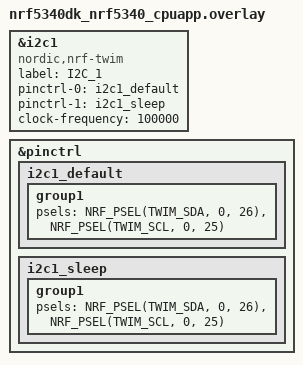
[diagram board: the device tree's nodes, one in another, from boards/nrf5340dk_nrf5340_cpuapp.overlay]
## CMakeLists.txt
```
# SPDX-License-Identifier: Apache-2.0

cmake_minimum_required(VERSION 3.20.0)
find_package(Zephyr REQUIRED HINTS $ENV{ZEPHYR_BASE})
project(max30100)

FILE(GLOB app_sources src/*.c)
target_sources(app PRIVATE ${app_sources})
```

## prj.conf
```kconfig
CONFIG_STDOUT_CONSOLE=y
CONFIG_LOG=y
CONFIG_I2C=y
CONFIG_SENSOR=y
CONFIG_SENSOR_LOG_LEVEL_DBG=y

CONFIG_ASSERT=y

# Logging
CONFIG_UART_CONSOLE=y
CONFIG_SERIAL=y


# Stacks and heaps
CONFIG_MAIN_STACK_SIZE=16384
CONFIG_HEAP_MEM_POOL_SIZE=16384

# I2C
CONFIG_NRFX_TWIM1=y


# Rebooot
CONFIG_REBOOT=n
CONFIG_RESET_ON_FATAL_ERROR=n
```

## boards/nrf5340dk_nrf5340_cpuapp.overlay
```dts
&i2c1 {
	status = "okay";
	compatible = "nordic,nrf-twim";
	label = "I2C_1";
	pinctrl-0 = <&i2c1_default>;
	pinctrl-1 = <&i2c1_sleep>;
	pinctrl-names = "default", "sleep";
	clock-frequency = <100000>; 
};

&pinctrl {
	i2c1_default: i2c1_default{
		group1 {
			psels = <NRF_PSEL(TWIM_SDA, 0, 26)>,
				<NRF_PSEL(TWIM_SCL, 0, 25)>;
		};
	};

	i2c1_sleep: i2c1_sleep{
		group1 {
			psels = <NRF_PSEL(TWIM_SDA, 0, 26)>,
				<NRF_PSEL(TWIM_SCL, 0, 25)>;
		};
	};
};
```

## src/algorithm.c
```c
#include "algorithm.h"

void maxim_heart_rate_and_oxygen_saturation(uint32_t *pun_ir_buffer, int32_t n_ir_buffer_length, uint32_t *pun_red_buffer, int32_t *pn_spo2, int8_t *pch_spo2_valid, int32_t *pn_heart_rate, int8_t *pch_hr_valid)
/**
* \brief        Calculate the heart rate and SpO2 level
* \par          Details
*               By detecting  peaks of PPG cycle and corresponding AC/DC of red/infra-red signal, the an_ratio for the SPO2 is computed.
*               Since this algorithm is aiming for Arm M0/M3. formaula for SPO2 did not achieve the accuracy due to register overflow.
*               Thus, accurate SPO2 is precalculated and save longo uch_spo2_table[] per each an_ratio.
*
* \param[in]    *pun_ir_buffer           - IR sensor data buffer
* \param[in]    n_ir_buffer_length      - IR sensor data buffer length
* \param[in]    *pun_red_buffer          - Red sensor data buffer
* \param[out]    *pn_spo2                - Calculated SpO2 value
* \param[out]    *pch_spo2_valid         - 1 if the calculated SpO2 value is valid
* \param[out]    *pn_heart_rate          - Calculated heart rate value
* \param[out]    *pch_hr_valid           - 1 if the calculated heart rate value is valid
*
* \retval       None
*/
{
    
  uint32_t un_ir_mean;
  int32_t k, n_i_ratio_count;
  int32_t i, n_exact_ir_valley_locs_count, n_middle_idx;
  int32_t n_th1, n_npks;   
  int32_t an_ir_valley_locs[15] ;
  int32_t n_peak_interval_sum;
  
  int32_t n_y_ac, n_x_ac;
  int32_t n_spo2_calc; 
  int32_t n_y_dc_max, n_x_dc_max; 
  int32_t n_y_dc_max_idx = 0;
  int32_t n_x_dc_max_idx = 0; 
  int32_t an_ratio[5], n_ratio_average; 
  int32_t n_nume, n_denom ;

  // calculates DC mean and subtract DC from ir
  un_ir_mean =0; 
  for (k=0 ; k<n_ir_buffer_length ; k++ ) un_ir_mean += pun_ir_buffer[k] ;
  un_ir_mean =un_ir_mean/n_ir_buffer_length ;
    
  // remove DC and invert signal so that we can use peak detector as valley detector
  for (k=0 ; k<n_ir_buffer_length ; k++ )  
    an_x[k] = -1*(pun_ir_buffer[k] - un_ir_mean) ; 
    
  // 4 pt Moving Average
  for(k=0; k< BUFFER_SIZE-MA4_SIZE; k++){
    an_x[k]=( an_x[k]+an_x[k+1]+ an_x[k+2]+ an_x[k+3])/(int32_t)4;        
  }
  // calculate threshold  
  n_th1=0; 
  for ( k=0 ; k<BUFFER_SIZE ;k++){
    n_th1 +=  an_x[k];
  }
  n_th1=  n_th1/ ( BUFFER_SIZE);
  if( n_th1<30) n_th1=30; // min allowed
  if( n_th1>60) n_th1=60; // max allowed

  for ( k=0 ; k<15;k++) an_ir_valley_locs[k]=0;
  // since we flipped signal, we use peak detector as valley detector
  maxim_find_peaks( an_ir_valley_locs, &n_npks, an_x, BUFFER_SIZE, n_th1, 4, 15 );//peak_height, peak_distance, max_num_peaks 
  n_peak_interval_sum =0;
  if (n_npks>=2){
    for (k=1; k<n_npks; k++) n_peak_interval_sum += (an_ir_valley_locs[k] -an_ir_valley_locs[k -1] ) ;
    n_peak_interval_sum =n_peak_interval_sum/(n_npks-1);
    *pn_heart_rate =(int32_t)( (FreqS*60)/ n_peak_interval_sum );
    *pch_hr_valid  = 1;
  }
  else  { 
    *pn_heart_rate = -999; // unable to calculate because # of peaks are too small
    *pch_hr_valid  = 0;
  }

  //  load raw value again for SPO2 calculation : RED(=y) and IR(=X)
  for (k=0 ; k<n_ir_buffer_length ; k++ )  {
      an_x[k] =  pun_ir_buffer[k] ; 
      an_y[k] =  pun_red_buffer[k] ; 
  }

  // find precise min near an_ir_valley_locs
  n_exact_ir_valley_locs_count =n_npks; 
  
  //using exact_ir_valley_locs , find ir-red DC andir-red AC for SPO2 calibration an_ratio
  //finding AC/DC maximum of raw

  n_ratio_average =0; 
  n_i_ratio_count = 0; 
  for(k=0; k< 5; k++) an_ratio[k]=0;
  for (k=0; k< n_exact_ir_valley_locs_count; k++){
    if (an_ir_valley_locs[k] > BUFFER_SIZE ){
      *pn_spo2 =  -999 ; // do not use SPO2 since valley loc is out of range
      *pch_spo2_valid  = 0; 
      return;
    }
  }
  // find max between two valley locations 
  // and use an_ratio betwen AC compoent of Ir & Red and DC compoent of Ir & Red for SPO2 
  for (k=0; k< n_exact_ir_valley_locs_count-1; k++){
    n_y_dc_max= -16777216 ; 
    n_x_dc_max= -16777216; 
    if (an_ir_valley_locs[k+1]-an_ir_valley_locs[k] >3){
        for (i=an_ir_valley_locs[k]; i< an_ir_valley_locs[k+1]; i++){
          if (an_x[i]> n_x_dc_max) {n_x_dc_max =an_x[i]; n_x_dc_max_idx=i;}
          if (an_y[i]> n_y_dc_max) {n_y_dc_max =an_y[i]; n_y_dc_max_idx=i;}
      }
      n_y_ac= (an_y[an_ir_valley_locs[k+1]] - an_y[an_ir_valley_locs[k] ] )*(n_y_dc_max_idx -an_ir_valley_locs[k]); //red
      n_y_ac=  an_y[an_ir_valley_locs[k]] + n_y_ac/ (an_ir_valley_locs[k+1] - an_ir_valley_locs[k])  ; 
      n_y_ac=  an_y[n_y_dc_max_idx] - n_y_ac;    // subracting linear DC compoenents from raw 
      n_x_ac= (an_x[an_ir_valley_locs[k+1]] - an_x[an_ir_valley_locs[k] ] )*(n_x_dc_max_idx -an_ir_valley_locs[k]); // ir
      n_x_ac=  an_x[an_ir_valley_locs[k]] + n_x_ac/ (an_ir_valley_locs[k+1] - an_ir_valley_locs[k]); 
      n_x_ac=  an_x[n_y_dc_max_idx] - n_x_ac;      // subracting linear DC compoenents from raw 
      n_nume=( n_y_ac *n_x_dc_max)>>7 ; //prepare X100 to preserve floating value
      n_denom= ( n_x_ac *n_y_dc_max)>>7;
      if (n_denom>0  && n_i_ratio_count <5 &&  n_nume != 0)
      {   
        an_ratio[n_i_ratio_count]= (n_nume*100)/n_denom ; //formular is ( n_y_ac *n_x_dc_max) / ( n_x_ac *n_y_dc_max) ;
        n_i_ratio_count++;
      }
    }
  }
  // choose median value since PPG signal may varies from beat to beat
  maxim_sort_ascend(an_ratio, n_i_ratio_count);
  n_middle_idx= n_i_ratio_count/2;

  if (n_middle_idx >1)
    n_ratio_average =( an_ratio[n_middle_idx-1] +an_ratio[n_middle_idx])/2; // use median
  else
    n_ratio_average = an_ratio[n_middle_idx ];

  if( n_ratio_average>2 && n_ratio_average <184){
    n_spo2_calc= uch_spo2_table[n_ratio_average] ;
    *pn_spo2 = n_spo2_calc ;
    *pch_spo2_valid  = 1;//  float_SPO2 =  -45.060*n_ratio_average* n_ratio_average/10000 + 30.354 *n_ratio_average/100 + 94.845 ;  // for comparison with table
  }
  else{
    *pn_spo2 =  -999 ; // do not use SPO2 since signal an_ratio is out of range
    *pch_spo2_valid  = 0; 
  }
}


void maxim_find_peaks( int32_t *pn_locs, int32_t *n_npks,  int32_t  *pn_x, int32_t n_size, int32_t n_min_height, int32_t n_min_distance, int32_t n_max_num )
/**
* \brief        Find peaks
* \par          Details
*               Find at most MAX_NUM peaks above MIN_HEIGHT separated by at least MIN_DISTANCE
*
* \retval       None
*/
{
  maxim_peaks_above_min_height( pn_locs, n_npks, pn_x, n_size, n_min_height );
  maxim_remove_close_peaks( pn_locs, n_npks, pn_x, n_min_distance );
  *n_npks = min( *n_npks, n_max_num );
}

void maxim_peaks_above_min_height( int32_t *pn_locs, int32_t *n_npks,  int32_t  *pn_x, int32_t n_size, int32_t n_min_height )
/**
* \brief        Find peaks above n_min_height
* \par          Details
*               Find all peaks above MIN_HEIGHT
*
* \retval       None
*/
{
  int32_t i = 1, n_width;
  *n_npks = 0;
  
  while (i < n_size-1){
    if (pn_x[i] > n_min_height && pn_x[i] > pn_x[i-1]){      // find left edge of potential peaks
      n_width = 1;
      while (i+n_width < n_size && pn_x[i] == pn_x[i+n_width])  // find flat peaks
        n_width++;
      if (pn_x[i] > pn_x[i+n_width] && (*n_npks) < 15 ){      // find right edge of peaks
        pn_locs[(*n_npks)++] = i;    
        // for flat peaks, peak location is left edge
        i += n_width+1;
      }
      else
        i += n_width;
    }
    else
      i++;
  }
}

void maxim_remove_close_peaks(int32_t *pn_locs, int32_t *pn_npks, int32_t *pn_x, int32_t n_min_distance)
/**
* \brief        Remove peaks
* \par          Details
*               Remove peaks separated by less than MIN_DISTANCE
*
* \retval       None
*/
{
    
  int32_t i, j, n_old_npks, n_dist;
    
  /* Order peaks from large to small */
  maxim_sort_indices_descend( pn_x, pn_locs, *pn_npks );

  for ( i = -1; i < *pn_npks; i++ ){
    n_old_npks = *pn_npks;
    *pn_npks = i+1;
    for ( j = i+1; j < n_old_npks; j++ ){
      n_dist =  pn_locs[j] - ( i == -1 ? -1 : pn_locs[i] ); // lag-zero peak of autocorr is at index -1
      if ( n_dist > n_min_distance || n_dist < -n_min_distance )
        pn_locs[(*pn_npks)++] = pn_locs[j];
    }
  }

  // Resort indices int32_to ascending order
  maxim_sort_ascend( pn_locs, *pn_npks );
}

void maxim_sort_ascend(int32_t  *pn_x, int32_t n_size) 
/**
* \brief        Sort array
* \par          Details
*               Sort array in ascending order (insertion sort algorithm)
*
* \retval       None
*/
{
  int32_t i, j, n_temp;
  for (i = 1; i < n_size; i++) {
    n_temp = pn_x[i];
    for (j = i; j > 0 && n_temp < pn_x[j-1]; j--)
        pn_x[j] = pn_x[j-1];
    pn_x[j] = n_temp;
  }
}

void maxim_sort_indices_descend(  int32_t  *pn_x, int32_t *pn_indx, int32_t n_size)
/**
* \brief        Sort indices
* \par          Details
*               Sort indices according to descending order (insertion sort algorithm)
*
* \retval       None
*/ 
{
  int32_t i, j, n_temp;
  for (i = 1; i < n_size; i++) {
    n_temp = pn_indx[i];
    for (j = i; j > 0 && pn_x[n_temp] > pn_x[pn_indx[j-1]]; j--)
      pn_indx[j] = pn_indx[j-1];
    pn_indx[j] = n_temp;
  }
}
```

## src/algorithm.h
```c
#include <stdbool.h>
#include <stdint.h>


#define FreqS 25    //sampling frequency
#define BUFFER_SIZE (FreqS * 4) 
#define MA4_SIZE 4 // DONOT CHANGE
#define min(x,y) ((x) < (y) ? (x) : (y)) //Defined in Arduino.h

//uch_spo2_table is approximated as  -45.060*ratioAverage* ratioAverage + 30.354 *ratioAverage + 94.845 ;
const uint8_t uch_spo2_table[184]={ 95, 95, 95, 96, 96, 96, 97, 97, 97, 97, 97, 98, 98, 98, 98, 98, 99, 99, 99, 99, 
              99, 99, 99, 99, 100, 100, 100, 100, 100, 100, 100, 100, 100, 100, 100, 100, 100, 100, 100, 100, 
              100, 100, 100, 100, 99, 99, 99, 99, 99, 99, 99, 99, 98, 98, 98, 98, 98, 98, 97, 97, 
              97, 97, 96, 96, 96, 96, 95, 95, 95, 94, 94, 94, 93, 93, 93, 92, 92, 92, 91, 91, 
              90, 90, 89, 89, 89, 88, 88, 87, 87, 86, 86, 85, 85, 84, 84, 83, 82, 82, 81, 81, 
              80, 80, 79, 78, 78, 77, 76, 76, 75, 74, 74, 73, 72, 72, 71, 70, 69, 69, 68, 67, 
              66, 66, 65, 64, 63, 62, 62, 61, 60, 59, 58, 57, 56, 56, 55, 54, 53, 52, 51, 50, 
              49, 48, 47, 46, 45, 44, 43, 42, 41, 40, 39, 38, 37, 36, 35, 34, 33, 31, 30, 29, 
              28, 27, 26, 25, 23, 22, 21, 20, 19, 17, 16, 15, 14, 12, 11, 10, 9, 7, 6, 5, 
              3, 2, 1 } ;
static  int32_t an_x[ BUFFER_SIZE]; //ir
static  int32_t an_y[ BUFFER_SIZE]; //red



void maxim_heart_rate_and_oxygen_saturation(uint32_t *pun_ir_buffer, int32_t n_ir_buffer_length, uint32_t *pun_red_buffer, int32_t *pn_spo2, int8_t *pch_spo2_valid, int32_t *pn_heart_rate, int8_t *pch_hr_valid);

//void maxim_heart_rate_and_oxygen_saturation(uint32_t *pun_ir_buffer, int32_t n_ir_buffer_length, uint32_t *pun_red_buffer);

void maxim_find_peaks(int32_t *pn_locs, int32_t *n_npks,  int32_t  *pn_x, int32_t n_size, int32_t n_min_height, int32_t n_min_distance, int32_t n_max_num);
void maxim_peaks_above_min_height(int32_t *pn_locs, int32_t *n_npks,  int32_t  *pn_x, int32_t n_size, int32_t n_min_height);
void maxim_remove_close_peaks(int32_t *pn_locs, int32_t *pn_npks, int32_t *pn_x, int32_t n_min_distance);
void maxim_sort_ascend(int32_t  *pn_x, int32_t n_size);
void maxim_sort_indices_descend(int32_t  *pn_x, int32_t *pn_indx, int32_t n_size);
```

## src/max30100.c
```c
#include "max30102.h"

const struct device *dev_i2c;

int MAX30102_check(const struct device *dev_i2c)
{
    uint8_t partid[1] = {0x0};
    int ret = i2c_burst_read(dev_i2c, MAX30102_ADDRESS, MAX30102_PARTID, partid, 1);    // Read part ID 
	
    if(ret) printk("MAX30102 not present!\n");
    else
      {
      if (partid[0] == 0x15) printk("MAX30102: present! Part ID: %dd\n", partid[0]);
      else
        { 
        printk("MAX30102: Error! Part ID: %dd\n", partid[0]);
        ret = 0;
        }
      }
    return ret;
}

int MAX30102_reset(const struct device *dev_i2c)     // This function resets the MAX30102
{
    uint8_t sendbuf[1] = {MAX30102_RESET};
    int ret = i2c_reg_write_byte(dev_i2c, MAX30102_ADDRESS, MAX30102_MODE_CONFIG, sendbuf[0]);
	
    if(ret) printk("Reset Error!\n");
    else printk("Reset done!\n");
    return ret;
}

int MAX30102_clear(const struct device *dev_i2c)     // Reads/clears the interrupt status register
{
    uint8_t IntStatus1[1] = {0x0};
    int ret = i2c_burst_read(dev_i2c, MAX30102_ADDRESS, MAX30102_INT_STATUS_1, IntStatus1, 1);
    
    if(ret) printk("MAX30102: Interrupt Status 1: Error!\n");
    else printk("MAX30102: Interrupt Status 1: Ok (%d)\n", IntStatus1[0]);
    return ret;
}

int MAX30102_config(const struct device *dev_i2c)     
{
    uint8_t buf[1] = {0x00};
    int ret, ret1 = 0;

    buf[0] = 0xC0;
    ret =  i2c_reg_write_byte(dev_i2c, MAX30102_ADDRESS, MAX30102_INT_ENABLE_1, buf[0]);
    if(ret)
      {
      ret1 = 0;
      }

    buf[0] = 0x00;
    ret =  i2c_reg_write_byte(dev_i2c, MAX30102_ADDRESS, MAX30102_INT_ENABLE_2, buf[0]); 
    if(ret) 
      {
      ret1 = 0;
      }

    buf[0] = 0x00;
     ret =  i2c_reg_write_byte(dev_i2c, MAX30102_ADDRESS, MAX30102_FIFO_WRITE_PTR, buf[0]); 
    if(ret)
      {
      ret1 = 0;      
      }

    buf[0] = 0x00;
    ret =  i2c_reg_write_byte(dev_i2c, MAX30102_ADDRESS, MAX30102_OVERFLOW_COUNT, buf[0]);  
    if(ret)
      {
      ret1 = 0;    
      }

    buf[0] = 0x00;
    ret =  i2c_reg_write_byte(dev_i2c, MAX30102_ADDRESS, MAX30102_FIFO_READ_PTR, buf[0]); 
    if(ret)
      {
      ret1 = 0;
      }

    buf[0] = 0x0F; // sample avg = 1, fifo rollover=false, fifo almost full = 17
    ret =  i2c_reg_write_byte(dev_i2c, MAX30102_ADDRESS, MAX30102_FIFO_CONFIG, buf[0]); 
    
    if(ret)
      {
      ret1 = 0;
      }

    buf[0] = 0x03; // 0x02 for Red only, 0x03 for SpO2 mode 0x07 multimode LED
    ret =  i2c_reg_write_byte(dev_i2c, MAX30102_ADDRESS, MAX30102_MODE_CONFIG, buf[0]);
    if(ret)
      {
      ret1 = 0;    
      }

    buf[0] = 0x27; // SPO2_ADC range = 4096nA, SPO2 sample rate (100 Hz), LED pulseWidth (400uS)
    ret =  i2c_reg_write_byte(dev_i2c, MAX30102_ADDRESS, MAX30102_SPO2_CONFIG, buf[0]);
    if(ret)
      {
      ret1 = 0;    
      }

    buf[0] = 0x24; // LED1 current ~ 7mA 
    ret =  i2c_reg_write_byte(dev_i2c, MAX30102_ADDRESS, MAX30102_LED1_PULSE_AMP, buf[0]);  
    if(ret)
      {
      ret1 = 0;
      }

    buf[0] = 0x24; // LED2 current ~ 7mA 
    ret =  i2c_reg_write_byte(dev_i2c, MAX30102_ADDRESS, MAX30102_LED2_PULSE_AMP, buf[0]);  
    if(ret)
      {
      ret1 = 0;   
      }
    return ret1;
}

bool MAX30102_read_reg(const struct device *dev_i2c, uint8_t uch_addr, uint8_t *puch_data)
{
  int ret;
  uint8_t buf[1] = {0x00};

  ret = i2c_burst_read(dev_i2c, MAX30102_ADDRESS, uch_addr, buf, 1);  
  if(ret)
  {  
    printk("MAX30102: Error!\n");
    return false;
  }
  else 
  {
    *puch_data = buf[0];
    return true;
  }
}

bool MAX30102_read_fifo(const struct device *dev_i2c, uint32_t *pun_red_led, uint32_t *pun_ir_led)
{
  int ret;
  uint32_t un_temp;
  unsigned char uch_temp;
  *pun_red_led=0;
  *pun_ir_led=0;
  char ach_i2c_data[6];
  
  //read and clear status register
  MAX30102_read_reg(dev_i2c, MAX30102_INT_STATUS_1, &uch_temp);
  MAX30102_read_reg(dev_i2c, MAX30102_INT_STATUS_2, &uch_temp);

  ret = i2c_burst_read(dev_i2c, MAX30102_ADDRESS, MAX30102_REG_FIFO_DATA, ach_i2c_data, 6);
  if(ret) printk("MAX30102: maxim_max30102_read_fifo Error!\n");

  un_temp=(unsigned char) ach_i2c_data[0];
  un_temp<<=16;
  *pun_red_led+=un_temp;
  un_temp=(unsigned char) ach_i2c_data[1];
  un_temp<<=8;
  *pun_red_led+=un_temp;
  un_temp=(unsigned char) ach_i2c_data[2];
  *pun_red_led+=un_temp;
  
  un_temp=(unsigned char) ach_i2c_data[3];
  un_temp<<=16;
  *pun_ir_led+=un_temp;
  un_temp=(unsigned char) ach_i2c_data[4];
  un_temp<<=8;
  *pun_ir_led+=un_temp;
  un_temp=(unsigned char) ach_i2c_data[5];
  *pun_ir_led+=un_temp;
  *pun_red_led&=0x03FFFF;
  *pun_ir_led&=0x03FFFF;

  return true;
}
```

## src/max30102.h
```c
#ifndef MAX30102_H_
#define MAX30102_H_

#include <zephyr/zephyr.h>
#include <stdio.h>
#include <string.h>
#include <stdlib.h>
#include <drivers/i2c.h>
#include <device.h>
#include <math.h>
#include <sys/printk.h>
#include <stdbool.h>
#include <stdint.h>

#define MAX30102_ADDRESS  0x57 //I2C Address for MAX30102

#define MAX30102_INT_STATUS_1        0x00
#define MAX30102_INT_STATUS_2        0x01
#define MAX30102_INT_ENABLE_1        0x02
#define MAX30102_INT_ENABLE_2        0x03
#define MAX30102_FIFO_WRITE_PTR      0x04
#define MAX30102_OVERFLOW_COUNT      0x05
#define MAX30102_FIFO_READ_PTR       0x06
#define MAX30102_REG_FIFO_DATA       0x07
#define MAX30102_FIFO_CONFIG         0x08
#define MAX30102_MODE_CONFIG         0x09
#define MAX30102_SPO2_CONFIG         0x0A
#define MAX30102_LED1_PULSE_AMP      0x0C
#define MAX30102_LED2_PULSE_AMP      0x0D
#define MAX30102_PARTID              0xFF
#define MAX30102_RESET               0x40

int MAX30102_clear(const struct device *dev_i2c);
int MAX30102_config(const struct device *dev_i2c);
int MAX30102_reset(const struct device *dev_i2c);
int MAX30102_check(const struct device *dev_i2c);
bool MAX30102_read_reg(const struct device *dev_i2c, uint8_t uch_addr, uint8_t *puch_data);
bool MAX30102_read_fifo(const struct device *dev_i2c, uint32_t *pun_red_led, uint32_t *pun_ir_led);

#endif /* MAX30102_H_ */
```
